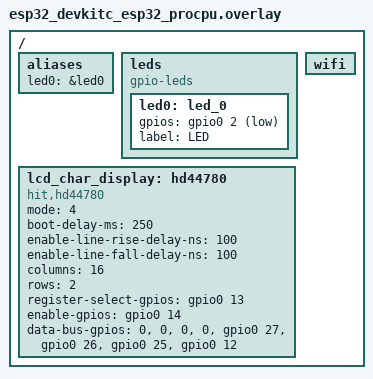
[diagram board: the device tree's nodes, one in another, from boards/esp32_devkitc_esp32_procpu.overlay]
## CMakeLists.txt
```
# SPDX-License-Identifier: Apache-2.0

cmake_minimum_required(VERSION 3.20.0)

# Print the value of the ZEPHYR_BASE environment variable during configure
message(STATUS "ZEPHYR_BASE environment variable: $ENV{ZEPHYR_BASE}")

if(EXISTS "${CMAKE_CURRENT_LIST_DIR}/private/wifi-network.conf")
  set(EXTRA_CONF_FILE "private/wifi-network.conf")
endif()

find_package(Zephyr REQUIRED HINTS $ENV{ZEPHYR_BASE})
project(wifi-clock)

target_include_directories(app PRIVATE src)
target_sources(app PRIVATE
  src/main.c
  src/wifi.c
  src/led.c
  src/network_time.c
  src/display.c
  src/clock.c
)
```

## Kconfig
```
mainmenu "ESP32 Zephyr Scaffold Configuration"
source "Kconfig.zephyr"

menu "Application Options"

config WIFI_SSID
	string "WiFi SSID"
	default "NO_SSID_SET"
	help
	  Determines which WiFi SSID to connect to.

config WIFI_PASSPHRASE
	string "WiFi passphrase"
	default "NO_PASSPHRASE_SET"
	help
	  The passphrase for the WiFi SSID.

config WIFI_TIMEOUT_MS
    int "WiFi connection timeout (ms)"
    default 60000
    help
      The timeout in milliseconds for connecting to the WiFi network.

config DHCP_TIMEOUT_MS
    int "DHCP timeout (ms)"
    default 30000
    help
      The timeout in milliseconds for obtaining an IP address via DHCP.

endmenu
```

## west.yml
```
manifest:
  remotes:
    - name: zephyrproject-rtos
      url-base: https://github.com/zephyrproject-rtos
  projects:
    - name: zephyr
      remote: zephyrproject-rtos
      revision: v4.2.1
      import:
        path-prefix: deps
  self:
    path: app
```

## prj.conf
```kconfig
CONFIG_NETWORKING=y
CONFIG_NET_L2_ETHERNET=y
CONFIG_NET_IPV4=y
CONFIG_NET_IPV6=n
CONFIG_NET_DHCPV4=y
CONFIG_NET_MGMT=y
CONFIG_NET_MGMT_EVENT=y
CONFIG_NET_CONNECTION_MANAGER=y
CONFIG_DNS_RESOLVER=y

CONFIG_SHELL=y
CONFIG_SHELL_BACKEND_SERIAL=y

# Network shell (includes general networking commands)
CONFIG_NET_SHELL=y

# Logging
CONFIG_LOG=y
CONFIG_LOG_DEFAULT_LEVEL=3
CONFIG_LOG_MODE_DEFERRED=y
CONFIG_LOG_CMDS=y

CONFIG_NET_LOG=y

CONFIG_EVENTS=y
CONFIG_ZBUS=y
CONFIG_SNTP=y

CONFIG_POSIX_API=y
```

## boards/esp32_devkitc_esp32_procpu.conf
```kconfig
CONFIG_BOOTLOADER_MCUBOOT=y

# There is an issue with using picolibc with the ESP32 toolchain.
CONFIG_NEWLIB_LIBC=y

CONFIG_WIFI=y
CONFIG_WIFI_ESP32=y

CONFIG_AUXDISPLAY=y
CONFIG_AUXDISPLAY_HD44780=y
```

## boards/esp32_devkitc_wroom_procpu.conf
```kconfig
CONFIG_BOOTLOADER_MCUBOOT=y

# There is an issue with using picolibc with the ESP32 toolchain.
CONFIG_NEWLIB_LIBC=y

CONFIG_WIFI=y
CONFIG_WIFI_ESP32=y
```

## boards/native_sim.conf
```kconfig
CONFIG_GPIO=y
CONFIG_GPIO_EMUL=y
CONFIG_NET_SOCKETS=y
```

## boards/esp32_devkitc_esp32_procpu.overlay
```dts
/ {
	aliases {
		led0 = &led0;
		/* sw0 = &button0; */
	};

	leds {
		compatible = "gpio-leds";
		led0: led_0 {
			gpios = <&gpio0 2 GPIO_ACTIVE_LOW>;
			label = "LED";
		};
	};

	wifi {
		status = "okay";
	};

	lcd_char_display: hd44780 {
		compatible = "hit,hd44780";
		status = "okay";

		mode = <4>;

		boot-delay-ms = <250>;
		enable-line-rise-delay-ns = <100>;
		enable-line-fall-delay-ns = <100>;

		/* Display dimensions */
		columns = <16>;
		rows = <2>;

		/* Control pins */
		register-select-gpios = <&gpio0 13 GPIO_ACTIVE_HIGH>;  /* RS */
		enable-gpios = <&gpio0 14 GPIO_ACTIVE_HIGH>;           /* E */
		/*read-write-gpios = <&gpio0 32 GPIO_ACTIVE_HIGH>;*/           /* RW */

		/* Data bus - 4-bit mode uses D4-D7 */
		data-bus-gpios = <0>,  /* D0 */
						 <0>,  /* D1 */
						 <0>,  /* D2 */
						 <0>,  /* D3 */
						 <&gpio0 27 GPIO_ACTIVE_HIGH>,  /* D4 */
						 <&gpio0 26 GPIO_ACTIVE_HIGH>,  /* D5 */
						 <&gpio0 25 GPIO_ACTIVE_HIGH>,  /* D6 */
						 <&gpio0 12 GPIO_ACTIVE_HIGH>;  /* D7 */
	};

	/* Optional: Button configuration
	buttons {
		compatible = "gpio-keys";
		button0: button_0 {
			gpios = <&gpio0 0 (GPIO_PULL_UP | GPIO_ACTIVE_LOW)>;
			label = "User button";
		};
	};
	*/
};
```

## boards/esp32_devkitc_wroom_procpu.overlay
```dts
/ {
	aliases {
		led0 = &led0;
		/* sw0 = &button0; */
	};

	leds {
		compatible = "gpio-leds";
		led0: led_0 {
			gpios = <&gpio0 2 GPIO_ACTIVE_LOW>;
			label = "LED";
		};
	};

	wifi {
		status = "okay";
	};

	/* Optional: Button configuration
	buttons {
		compatible = "gpio-keys";
		button0: button_0 {
			gpios = <&gpio0 0 (GPIO_PULL_UP | GPIO_ACTIVE_LOW)>;
			label = "User button";
		};
	};
	*/
};
```

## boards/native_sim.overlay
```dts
/ {
	aliases {
		led0 = &led0;
	};

	leds {
		compatible = "gpio-leds";
		led0: led_0 {
			gpios = <&gpio0 0 GPIO_ACTIVE_LOW>;
			label = "LED";
		};
	};

	wifi {
		status = "okay";
	};
};
```

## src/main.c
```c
#include "clock.h"
#include "display.h"
#include "network_time.h"
#include "wifi.h"
#include "zephyr/kernel.h"
#include "zephyr/logging/log.h"
#include <zephyr/zbus/zbus.h>

LOG_MODULE_REGISTER(main, CONFIG_LOG_DEFAULT_LEVEL);

ZBUS_SUBSCRIBER_DEFINE(network_wifi_sub, 4);

int main(void)
{
	display_init();
	clock_init();
	display_show_message("Connecting WiFi");

	while (1) {
		const struct zbus_channel *chan;
		struct wifi_event_msg msg;

		if (zbus_sub_wait(&network_wifi_sub, &chan, K_FOREVER) != 0) {
			continue;
		}

		if (zbus_chan_read(chan, &msg, K_MSEC(100)) != 0) {
			continue;
		}

		if (msg.events & WIFI_EVENT_IP_ACQUIRED) {
			LOG_INF("Main thread: IP acquired");
			display_show_message("WiFi connected");
			uint32_t offset_ms = network_time_get_and_set();
			clock_start(offset_ms);
		}

		if (msg.events & WIFI_EVENT_DISCONNECTED) {
			LOG_INF("Main thread: Network disconnected");
			clock_stop();
			display_show_message("WiFi disconnect");
		}
	}

	return 0;
}
```

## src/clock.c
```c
#include "clock.h"

#include <time.h>

#include "display.h"
#include "zephyr/kernel.h"
#include "zephyr/logging/log.h"

LOG_MODULE_REGISTER(clock, CONFIG_LOG_DEFAULT_LEVEL);

ZBUS_CHAN_DEFINE(clock_event_chan, struct clock_event_msg, NULL, NULL, ZBUS_OBSERVERS_EMPTY,
		 ZBUS_MSG_INIT(.utc_time = {0}));

static struct k_timer one_second_timer;
static struct k_work clock_tick_work;

static void clock_tick_work_handler(struct k_work *work)
{
	struct timespec ts;
	struct tm tm_utc;
	time_t now;
	struct clock_event_msg msg;
	int ret;

	ARG_UNUSED(work);

	ret = clock_gettime(CLOCK_REALTIME, &ts);
	if (ret != 0) {
		LOG_ERR("Failed to get time: %d", ret);
		return;
	}

	now = ts.tv_sec;
	if (gmtime_r(&now, &tm_utc) == NULL) {
		LOG_ERR("Failed to convert time");
		return;
	}

	display_show_time(&tm_utc);

	msg.utc_time = tm_utc;
	ret = zbus_chan_pub(&clock_event_chan, &msg, K_NO_WAIT);
	if (ret != 0) {
		LOG_ERR("Failed to publish clock event: %d", ret);
	}
}

static void timer_handler(struct k_timer *timer)
{
	ARG_UNUSED(timer);
	k_work_submit(&clock_tick_work);
}

int clock_init(void)
{
	k_work_init(&clock_tick_work, clock_tick_work_handler);
	k_timer_init(&one_second_timer, timer_handler, NULL);
	return 0;
}

int clock_start(uint32_t offset_ms)
{
	if (offset_ms == 0) {
		offset_ms = 1;
	}

	k_timer_start(&one_second_timer, K_MSEC(offset_ms), K_SECONDS(1));
	return 0;
}

void clock_stop(void)
{
	k_timer_stop(&one_second_timer);
}
```

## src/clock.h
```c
#ifndef CLOCK_H
#define CLOCK_H

#include <stdint.h>
#include <time.h>

#include <zephyr/zbus/zbus.h>

struct clock_event_msg {
	struct tm utc_time;
};

ZBUS_CHAN_DECLARE(clock_event_chan);

int clock_init(void);
int clock_start(uint32_t offset_ms);
void clock_stop(void);

#endif /* CLOCK_H */
```

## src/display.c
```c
#include "display.h"

#include <string.h>

#include <zephyr/devicetree.h>
#include <zephyr/device.h>
#include <zephyr/drivers/auxdisplay.h>
#include <zephyr/kernel.h>
#include <zephyr/logging/log.h>

LOG_MODULE_REGISTER(display, CONFIG_LOG_DEFAULT_LEVEL);

#define LCD_NODE DT_NODELABEL(lcd_char_display)

static const struct device *lcd;
static const size_t lcd_cols = DT_PROP(LCD_NODE, columns);
static const size_t lcd_rows = DT_PROP(LCD_NODE, rows);

static bool display_ready(void)
{
	return (lcd != NULL) && device_is_ready(lcd);
}

static void display_write_centered_line(uint8_t row, const char *text)
{
	size_t len;
	size_t write_len;
	size_t col;
	char line[lcd_cols];

	if ((text == NULL) || (row >= lcd_rows)) {
		return;
	}

	len = strlen(text);
	write_len = (len > lcd_cols) ? lcd_cols : len;
	col = (lcd_cols - write_len) / 2;

	memset(line, ' ', lcd_cols);
	memcpy(line + col, text, write_len);

	auxdisplay_cursor_position_set(lcd, AUXDISPLAY_POSITION_ABSOLUTE, 0, row);
	auxdisplay_write(lcd, line, lcd_cols);
}

int display_init(void)
{
	lcd = DEVICE_DT_GET(DT_NODELABEL(lcd_char_display));

	while (!device_is_ready(lcd)) {
		LOG_INF("Waiting for LCD to be ready");
		k_sleep(K_SECONDS(1));
	}

	auxdisplay_clear(lcd);
	return 0;
}

void display_show_message(const char *msg)
{
	char line0[17] = {0};
	char line1[17] = {0};
	size_t i = 0;
	size_t line_len = 0;
	uint8_t row = 0;

	if (!display_ready()) {
		return;
	}

	auxdisplay_clear(lcd);
	if (msg == NULL) {
		return;
	}

	while (msg[i] != '\0' && row < lcd_rows) {
		if (msg[i] == '\n') {
			row++;
			line_len = 0;
			i++;
			continue;
		}

		if (line_len < lcd_cols) {
			if (row == 0) {
				line0[line_len] = msg[i];
			} else {
				line1[line_len] = msg[i];
			}
			line_len++;
		}
		i++;
	}

	display_write_centered_line(0, line0);
	display_write_centered_line(1, line1);
}

void display_show_time(const struct tm *time_utc)
{
	char time_str[17];
	char date_str[17];

	if (!display_ready() || (time_utc == NULL)) {
		return;
	}

	strftime(time_str, sizeof(time_str), "%H:%M:%S", time_utc);
	strftime(date_str, sizeof(date_str), "%Y-%m-%d", time_utc);

	display_write_centered_line(0, time_str);
	display_write_centered_line(1, date_str);
}
```

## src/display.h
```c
#ifndef DISPLAY_H
#define DISPLAY_H

#include <time.h>

int display_init(void);
void display_show_message(const char *msg);
void display_show_time(const struct tm *time_utc);

#endif /* DISPLAY_H */
```

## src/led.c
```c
#include <zephyr/kernel.h>
#include <zephyr/drivers/gpio.h>
#include <zephyr/logging/log.h>

LOG_MODULE_REGISTER(led, CONFIG_LOG_DEFAULT_LEVEL);

#define LED0_NODE DT_ALIAS(led0)
static const struct gpio_dt_spec led = GPIO_DT_SPEC_GET(LED0_NODE, gpios);

static void led_thread_fn(void *arg1, void *arg2, void *arg3)
{
    int ret;

    if (!gpio_is_ready_dt(&led)) {
        LOG_ERR("Error: LED device %s is not ready", led.port->name);
        return;
    }

    ret = gpio_pin_configure_dt(&led, GPIO_OUTPUT_ACTIVE);
    if (ret < 0) {
        LOG_ERR("Error: Cannot configure LED GPIO");
        return;
    }

    while (1) {
        ret = gpio_pin_toggle_dt(&led);
        if (ret < 0) {
            LOG_ERR("Error: Cannot toggle LED");
            return;
        }

        k_sleep(K_SECONDS(1));
    }
}

K_THREAD_DEFINE(led_thread, 512, led_thread_fn, NULL, NULL, NULL, 7, 0, 0);
```

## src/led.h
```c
#ifndef LED_H
#define LED_H

void led_init(void);

#endif // LED_H
```

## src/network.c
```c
#include "network.h"
#include "wifi.h"

#include "zephyr/kernel.h"
#include "zephyr/logging/log.h"

LOG_MODULE_REGISTER(network, CONFIG_LOG_DEFAULT_LEVEL);

K_EVENT_DEFINE(network_events);

static void network_event_forwarder(void *arg1, void *arg2, void *arg3)
{
	while (1) {
		uint32_t events = k_event_wait(&wifi_events,
					      WIFI_EVENT_DISCONNECTED | WIFI_EVENT_IP_ACQUIRED,
					      false, K_FOREVER);

		if (events & WIFI_EVENT_DISCONNECTED) {
			k_event_set(&network_events, NETWORK_EVENT_DISCONNECTED);
			k_event_clear(&wifi_events, WIFI_EVENT_DISCONNECTED);
			LOG_INF("Network disconnected event forwarded");
		}

		if (events & WIFI_EVENT_IP_ACQUIRED) {
			k_event_set(&network_events, NETWORK_EVENT_CONNECTED);
			k_event_clear(&wifi_events, WIFI_EVENT_IP_ACQUIRED);
			LOG_INF("Network connected event forwarded");
		}
	}
}

K_THREAD_DEFINE(network_event_thread, 2048, network_event_forwarder, NULL, NULL, NULL, 7, 0, 0);
```

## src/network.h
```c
#ifndef NETWORK_H
#define NETWORK_H

#include <zephyr/kernel.h>

#define NETWORK_EVENT_CONNECTED BIT(0)
#define NETWORK_EVENT_DISCONNECTED BIT(1)

extern struct k_event network_events;

#endif // NETWORK_H
```

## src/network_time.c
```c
#include "network_time.h"

#include <stdint.h>
#include <time.h>

#include "zephyr/kernel.h"
#include "zephyr/logging/log.h"
#include "zephyr/net/sntp.h"

LOG_MODULE_REGISTER(network_time, CONFIG_LOG_DEFAULT_LEVEL);

#define NTP_SERVER "pool.ntp.org"
#define NTP_TIMEOUT 3000
#define NTP_RETRY_COUNT 10

uint32_t network_time_get_and_set(void)
{
	struct sntp_time ts;
	int res;
	int retries = 0;
	uint32_t offset_ms = 1000;

	LOG_INF("Fetching time from NTP server: %s", NTP_SERVER);

	do {
		res = sntp_simple(NTP_SERVER, NTP_TIMEOUT, &ts);
		if (res >= 0) {
			break;
		}
		retries++;
		LOG_WRN("SNTP query failed (attempt %d/%d): %d", retries, NTP_RETRY_COUNT, res);
		if (retries < NTP_RETRY_COUNT) {
			k_msleep(1000); // Wait a bit before retrying
		}
	} while (retries < NTP_RETRY_COUNT);

	if (res < 0) {
		LOG_ERR("SNTP query failed after %d retries: %d", NTP_RETRY_COUNT, res);
		return offset_ms;
	}

	time_t now = (time_t)ts.seconds;
	uint64_t nsec = (uint64_t)ts.fraction * 1000000000ULL >> 32;
	uint32_t msec = (uint32_t)(nsec / 1000000ULL);
	struct tm *tm_struct;
	char time_str[64];

	tm_struct = gmtime(&now);
	if (tm_struct) {
		strftime(time_str, sizeof(time_str), "%Y-%m-%d %H:%M:%S", tm_struct);
		LOG_INF("Current time: %s.%03u UTC", time_str, msec);
	} else {
		LOG_ERR("Failed to convert time");
	}

	struct timespec tspec;
	tspec.tv_sec = now;
	tspec.tv_nsec = (long)nsec;
	clock_settime(CLOCK_REALTIME, &tspec);

	offset_ms = 1000 - msec;
	return offset_ms;
}
```

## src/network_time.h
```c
#ifndef NETWORK_TIME_H
#define NETWORK_TIME_H
#include "stdint.h"

uint32_t network_time_get_and_set(void);

#endif // NETWORK_TIME_H
```

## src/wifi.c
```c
#include "wifi.h"

#include <stdio.h>
#include <string.h>

#include "zephyr/net/net_if.h"
#include "zephyr/net/net_ip.h"
#include "zephyr/net/dhcpv4.h"
#include "zephyr/net/net_mgmt.h"
#include "zephyr/net/wifi_mgmt.h"
#include "zephyr/sys/atomic.h"
#include "zephyr/kernel.h"
#include <zephyr/zbus/zbus.h>

LOG_MODULE_REGISTER(wifi, CONFIG_LOG_DEFAULT_LEVEL);

#define WIFI_IFACE_NAME_MAX 32

ZBUS_CHAN_DEFINE(wifi_event_chan, struct wifi_event_msg, NULL, NULL, ZBUS_OBSERVERS(network_wifi_sub),
		 ZBUS_MSG_INIT(.events = 0));

static struct net_mgmt_event_callback wifi_cb;
static struct net_mgmt_event_callback wifi_disconnect_cb;
static atomic_t wifi_connected = ATOMIC_INIT(0);

static void publish_wifi_event(uint32_t events)
{
	const struct wifi_event_msg msg = {
		.events = events,
	};
	int ret = zbus_chan_pub(&wifi_event_chan, &msg, K_NO_WAIT);

	if (ret) {
		LOG_ERR("Failed to publish Wi-Fi event 0x%08x: %d", events, ret);
	}
}

#ifdef CONFIG_WIFI
static void wifi_mgmt_event_handler(struct net_mgmt_event_callback *cb,
                                   uint64_t mgmt_event,
                                   struct net_if *iface)
{
	    if (mgmt_event == NET_EVENT_WIFI_CONNECT_RESULT) {
	        struct wifi_status *status = (struct wifi_status *)cb->info;
	        if (status && status->status == 0) {
	            atomic_set(&wifi_connected, 1);
	            publish_wifi_event(WIFI_EVENT_CONNECTED);
	            LOG_INF("Wi-Fi connected event received");
	        } else {
	            LOG_ERR("Wi-Fi connect failed, status: %d", status ? status->status : -1);
	        }
	    } else if (mgmt_event == NET_EVENT_WIFI_DISCONNECT_RESULT) {
	        if (atomic_cas(&wifi_connected, 1, 0)) {
	            publish_wifi_event(WIFI_EVENT_DISCONNECTED);
	            LOG_INF("Wi-Fi disconnected event received");
	        } else {
	            LOG_DBG("Ignoring disconnect event before initial connect");
	        }
	    }
}
#endif

static struct net_mgmt_event_callback dns_cb;

static void dns_mgmt_event_handler(struct net_mgmt_event_callback *cb,
                                   uint64_t mgmt_event,
                                   struct net_if *iface)
{
    if (mgmt_event == NET_EVENT_DNS_SERVER_ADD) {
        LOG_INF("DNS server added event received");
        publish_wifi_event(WIFI_EVENT_DNS_CONFIGURED);
    }
}

static struct net_if *get_default_iface(void)
{
	struct net_if *iface = net_if_get_default();
	char iface_name[WIFI_IFACE_NAME_MAX] = {0};

	if (net_if_get_name(iface, iface_name, sizeof(iface_name)) > 0) {
		LOG_INF("iface: %s", iface_name);
	} else {
		LOG_INF("iface: <unknown>");
	}
	LOG_INF("up: %d", net_if_is_up(iface));
	return iface;
}

static bool wifi_credentials_configured(void)
{
	if ((strcmp(CONFIG_WIFI_SSID, "NO_SSID_SET") == 0) ||
	    (strcmp(CONFIG_WIFI_PASSPHRASE, "NO_PASSPHRASE_SET") == 0)) {
		return false;
	}

	return (CONFIG_WIFI_SSID[0] != '\0');
}

#ifdef CONFIG_WIFI
static void register_wifi_callbacks(void)
{
	net_mgmt_init_event_callback(&wifi_cb, wifi_mgmt_event_handler,
				     NET_EVENT_WIFI_CONNECT_RESULT);
	net_mgmt_add_event_callback(&wifi_cb);

	net_mgmt_init_event_callback(&wifi_disconnect_cb, wifi_mgmt_event_handler,
				     NET_EVENT_WIFI_DISCONNECT_RESULT);
	net_mgmt_add_event_callback(&wifi_disconnect_cb);
}

static int request_wifi_connect(struct net_if *iface)
{
	struct wifi_connect_req_params wifi_params = {
		.ssid = CONFIG_WIFI_SSID,
		.ssid_length = strlen(CONFIG_WIFI_SSID),
		.psk = CONFIG_WIFI_PASSPHRASE,
		.psk_length = strlen(CONFIG_WIFI_PASSPHRASE),
		.security = WIFI_SECURITY_TYPE_PSK,
		.channel = WIFI_CHANNEL_ANY,
		.mfp = WIFI_MFP_OPTIONAL,
	};

	int ret = net_mgmt(NET_REQUEST_WIFI_CONNECT, iface, &wifi_params,
			   sizeof(wifi_params));
	if (ret) {
		LOG_ERR("Wi-Fi connect request failed: %d", ret);
		return -1;
	}

	return 0;
}

static int wait_for_wifi_connected(void)
{
	uint32_t waited = 0;

	while (!atomic_get(&wifi_connected)) {
		k_msleep(100);
		waited += 100;
		if (waited >= CONFIG_WIFI_TIMEOUT_MS) {
			LOG_ERR("Wi-Fi connection timeout");
			return -1;
		}
	}

	LOG_INF("Wi-Fi connected (event)");
	return 0;
}
#endif

static void register_dns_callback(void)
{
	net_mgmt_init_event_callback(&dns_cb, dns_mgmt_event_handler,
				     NET_EVENT_DNS_SERVER_ADD);
	net_mgmt_add_event_callback(&dns_cb);
}

static int wait_for_dhcp_ipv4(struct net_if *iface)
{
	uint32_t dhcp_waited = 0;

	while (1) {
		struct in_addr *addr = net_if_ipv4_get_global_addr(iface, NET_ADDR_PREFERRED);
		if (addr && !net_ipv4_is_addr_unspecified(addr)) {
			LOG_INF("DHCP IP address assigned: %s",
				net_addr_ntop(AF_INET, addr,
					      (char[NET_IPV4_ADDR_LEN]){0},
					      NET_IPV4_ADDR_LEN));
			return 0;
		}

		k_msleep(100);
		dhcp_waited += 100;
		if (dhcp_waited >= CONFIG_DHCP_TIMEOUT_MS) {
			LOG_ERR("DHCP IP address assignment timeout");
			return -1;
		}
	}
}

int wifi_connect()
{
	if (!wifi_credentials_configured()) {
		LOG_ERR("Wi-Fi credentials not configured (CONFIG_WIFI_SSID / CONFIG_WIFI_PASSPHRASE)");
		publish_wifi_event(WIFI_EVENT_DISCONNECTED);
		return -1;
	}

	LOG_INF("Connecting to network: %s", CONFIG_WIFI_SSID);
	struct net_if *iface = get_default_iface();

#ifdef CONFIG_WIFI
	atomic_set(&wifi_connected, 0);
	printf("Using SSID: %s\n", CONFIG_WIFI_SSID);

	register_wifi_callbacks();
#endif

	register_dns_callback();

#ifdef CONFIG_WIFI
	if (request_wifi_connect(iface) != 0) {
		return -1;
	}

	if (wait_for_wifi_connected() != 0) {
		return -1;
	}
#endif

	LOG_INF("Starting DHCPv4...");
	net_dhcpv4_start(iface);

	return wait_for_dhcp_ipv4(iface);
}

static void wifi_thread_fn(void *arg1, void *arg2, void *arg3)
{
	int ret;

	LOG_INF("Wi-Fi thread started");

	while (1) {
		ret = wifi_connect();
		if (ret == 0) {
			LOG_INF("Wi-Fi connected successfully");
			publish_wifi_event(WIFI_EVENT_IP_ACQUIRED);
			break;
		}

		LOG_ERR("Wi-Fi connection failed, retrying in 5 seconds...");
		k_sleep(K_SECONDS(5));
	}
}

K_THREAD_DEFINE(wifi_thread, 4096, wifi_thread_fn, NULL, NULL, NULL, 7, 0, 0);
```

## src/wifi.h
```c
#ifndef WIFI_H
#define WIFI_H

#include <zephyr/kernel.h>
#include <zephyr/zbus/zbus.h>

#define WIFI_EVENT_CONNECTED    BIT(0)
#define WIFI_EVENT_DISCONNECTED BIT(1)
#define WIFI_EVENT_IP_ACQUIRED  BIT(2)
#define WIFI_EVENT_DNS_CONFIGURED BIT(3)

struct wifi_event_msg {
	uint32_t events;
};

ZBUS_OBS_DECLARE(network_wifi_sub);
ZBUS_CHAN_DECLARE(wifi_event_chan);

int wifi_connect();

#endif //WIFI_H
```
